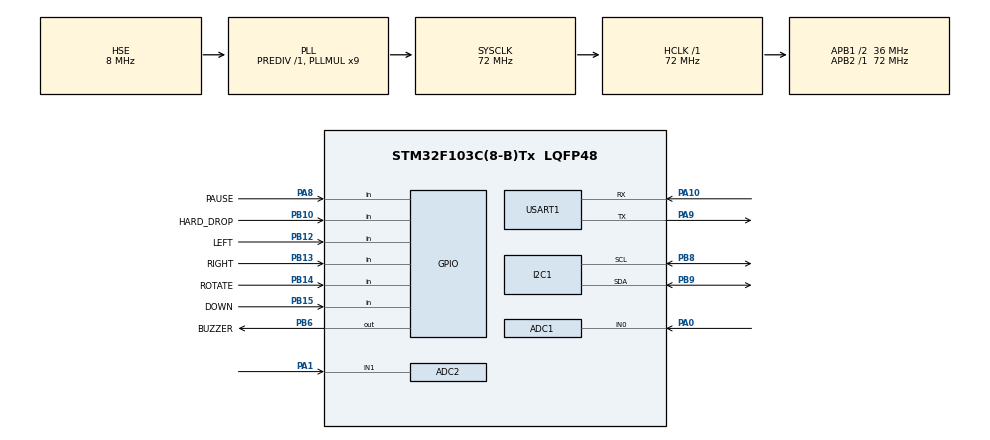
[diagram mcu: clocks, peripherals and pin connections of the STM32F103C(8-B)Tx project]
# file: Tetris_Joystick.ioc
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ADC1.Channel-0\#ChannelRegularConversion=ADC_CHANNEL_0
ADC1.NbrOfConversionFlag=1
ADC1.Rank-0\#ChannelRegularConversion=1
ADC1.SamplingTime-0\#ChannelRegularConversion=ADC_SAMPLETIME_55CYCLES_5
ADC1.master=1
ADC2.Channel-0\#ChannelRegularConversion=ADC_CHANNEL_1
ADC2.NbrOfConversionFlag=1
ADC2.Rank-0\#ChannelRegularConversion=1
ADC2.SamplingTime-0\#ChannelRegularConversion=ADC_SAMPLETIME_55CYCLES_5
FREERTOS.Queues01=xInputQueue,16,uint16_t,0,Dynamic,NULL,NULL;xFrameQueue,1,uint16_t,0,Dynamic,NULL,NULL
FREERTOS.Tasks01=InputTask,27,192,StartInputTask,Default,NULL,Dynamic,NULL,NULL;GameTask,26,320,StartGameTask,Default,NULL,Dynamic,NULL,NULL;DisplayTask,25,384,StartDisplayTask,Default,NULL,Dynamic,NULL,NULL
FREERTOS.configCHECK_FOR_STACK_OVERFLOW=2
FREERTOS.configIDLE_SHOULD_YIELD=0
FREERTOS.configTOTAL_HEAP_SIZE=8192
FREERTOS.configUSE_MALLOC_FAILED_HOOK=1
Mcu.Family=STM32F1
Mcu.Name=STM32F103C(8-B)Tx
Mcu.Package=LQFP48
NVIC.PriorityGroup=NVIC_PRIORITYGROUP_4
NVIC.TIM2_IRQn=true\:15\:0\:false\:false\:true\:false\:false\:true\:true
NVIC.TimeBase=TIM2_IRQn
NVIC.TimeBaseIP=TIM2
NVIC.USART1_IRQn=true\:6\:0\:false\:false\:true\:true\:true\:true
PA0-WKUP.Signal=ADCx_IN0
PA1.Signal=ADCx_IN1
PA10.Mode=Asynchronous
PA10.Signal=USART1_RX
PA13.Mode=Serial_Wire
PA13.Signal=SYS_JTMS-SWDIO
PA14.Mode=Serial_Wire
PA14.Signal=SYS_JTCK-SWCLK
PA8.GPIO_Label=PAUSE
PA8.GPIO_PuPd=GPIO_PULLUP
PA8.Signal=GPIO_Input
PA9.Mode=Asynchronous
PA9.Signal=USART1_TX
PB10.GPIO_Label=HARD_DROP
PB10.GPIO_PuPd=GPIO_PULLUP
PB10.Signal=GPIO_Input
PB12.GPIO_Label=LEFT
PB12.GPIO_PuPd=GPIO_PULLUP
PB12.Signal=GPIO_Input
PB13.GPIO_Label=RIGHT
PB13.GPIO_PuPd=GPIO_PULLUP
PB13.Signal=GPIO_Input
PB14.GPIO_Label=ROTATE
PB14.GPIO_PuPd=GPIO_PULLUP
PB14.Signal=GPIO_Input
PB15.GPIO_Label=DOWN
PB15.GPIO_PuPd=GPIO_PULLUP
PB15.Signal=GPIO_Input
PB6.Signal=GPIO_Output
PB6.GPIO_Label=BUZZER
PB6.PinState=GPIO_PIN_SET
PB8.Mode=I2C
PB8.Signal=I2C1_SCL
PB9.Mode=I2C
PB9.Signal=I2C1_SDA
PD0-OSC_IN.Mode=HSE-External-Oscillator
PD0-OSC_IN.Signal=RCC_OSC_IN
PD1-OSC_OUT.Mode=HSE-External-Oscillator
PD1-OSC_OUT.Signal=RCC_OSC_OUT
ProjectManager.HeapSize=0x200
ProjectManager.StackSize=0x400
ProjectManager.TargetToolchain=MDK-ARM V5.32
RCC.ADCPresc=RCC_ADCPCLK2_DIV6
RCC.AHBFreq_Value=72000000
RCC.APB1CLKDivider=RCC_HCLK_DIV2
RCC.APB1Freq_Value=36000000
RCC.APB1TimFreq_Value=72000000
RCC.APB2Freq_Value=72000000
RCC.APB2TimFreq_Value=72000000
RCC.HCLKFreq_Value=72000000
RCC.PLLMUL=RCC_PLL_MUL9
RCC.PLLSourceVirtual=RCC_PLLSOURCE_HSE
RCC.SYSCLKFreq_VALUE=72000000
RCC.SYSCLKSource=RCC_SYSCLKSOURCE_PLLCLK
RCC.USBFreq_Value=72000000
SH.ADCx_IN0.0=ADC1_IN0,IN0
SH.ADCx_IN1.0=ADC2_IN1,IN1
USART1.VirtualMode=VM_ASYNC
VP_FREERTOS_VS_CMSIS_V2.Mode=CMSIS_V2
VP_SYS_VS_tim2.Mode=TIM2
board=custom

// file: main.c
/* USER CODE BEGIN Header */
/**
  ******************************************************************************
  * @file           : main.c
  * @brief          : Main program body
  ******************************************************************************
  * @attention
  *
  * Copyright (c) 2026 STMicroelectronics.
  * All rights reserved.
  *
  * This software is licensed under terms that can be found in the LICENSE file
  * in the root directory of this software component.
  * If no LICENSE file comes with this software, it is provided AS-IS.
  *
  ******************************************************************************
  */
/* USER CODE END Header */
#include "main.h"
#include "cmsis_os.h"

/* USER CODE BEGIN Includes */
#include "app_shared.h"
#include "app_diagnostics.h"
#include "hal_buzzer.h"

/* USER CODE END Includes */

ADC_HandleTypeDef hadc1;
ADC_HandleTypeDef hadc2;

I2C_HandleTypeDef hi2c1;

UART_HandleTypeDef huart1;

/* Definitions for InputTask */
osThreadId_t InputTaskHandle;
const osThreadAttr_t InputTask_attributes = {
  .name = "InputTask",
  .stack_size = APP_INPUT_STACK_BYTES,
  .priority = (osPriority_t) APP_INPUT_PRIORITY,
};
/* Definitions for GameTask */
osThreadId_t GameTaskHandle;
const osThreadAttr_t GameTask_attributes = {
  .name = "GameTask",
  .stack_size = APP_GAME_STACK_BYTES,
  .priority = (osPriority_t) APP_GAME_PRIORITY,
};
/* Definitions for DisplayTask */
osThreadId_t DisplayTaskHandle;
const osThreadAttr_t DisplayTask_attributes = {
  .name = "DisplayTask",
  .stack_size = APP_DISPLAY_STACK_BYTES,
  .priority = (osPriority_t) APP_DISPLAY_PRIORITY,
};
/* Definitions for xInputQueue */
osMessageQueueId_t xInputQueueHandle;
const osMessageQueueAttr_t xInputQueue_attributes = {
  .name = "xInputQueue"
};
/* Definitions for xFrameQueue */
osMessageQueueId_t xFrameQueueHandle;
const osMessageQueueAttr_t xFrameQueue_attributes = {
  .name = "xFrameQueue"
};

void SystemClock_Config(void);
static void MX_GPIO_Init(void);
static void MX_ADC1_Init(void);
static void MX_ADC2_Init(void);
static void MX_I2C1_Init(void);
static void MX_USART1_UART_Init(void);
void StartInputTask(void *argument);
void StartGameTask(void *argument);
void StartDisplayTask(void *argument);

int main(void)
{

  /* MCU Configuration--------------------------------------------------------*/

  /* Reset of all peripherals, Initializes the Flash interface and the Systick. */
  HAL_Init();
  MX_GPIO_Init(); /* Drive active-low buzzer HIGH before clock/peripheral setup. */

  /* Configure the system clock */
  SystemClock_Config();

  /* Initialize all configured peripherals */
  MX_I2C1_Init();
  MX_USART1_UART_Init();
  MX_ADC1_Init();
  MX_ADC2_Init();
  /* USER CODE BEGIN 2 */
  if (HAL_ADCEx_Calibration_Start(&hadc1)!=HAL_OK ||
      HAL_ADCEx_Calibration_Start(&hadc2)!=HAL_OK) Error_Handler();

  /* USER CODE END 2 */

  /* Ca nhom phai nam: init phan cung -> kernel -> 2 Queue -> 3 Task
   * -> scheduler. Task chua chay cho den khi kernel duoc start. */
  /* Init scheduler */
  if (osKernelInitialize()!=osOK) Error_Handler();

  /* Queue input: 16 phan tu uint16_t. Queue frame: 1 token uint16_t.
   * Snapshot lon duoc copy qua API rieng, khong nham size token voi frame. */
  /* Create the queue(s) */
  /* creation of xInputQueue */
  xInputQueueHandle = osMessageQueueNew (16, sizeof(uint16_t), &xInputQueue_attributes);

  /* creation of xFrameQueue */
  xFrameQueueHandle = osMessageQueueNew (1, sizeof(uint16_t), &xFrameQueue_attributes);

  /* Tao dung mot lan. Cac ham task_*_run trong app/ khong tu tao thread. */
  /* Create the thread(s) */
  /* creation of InputTask */
  InputTaskHandle = osThreadNew(StartInputTask, NULL, &InputTask_attributes);

  /* creation of GameTask */
  GameTaskHandle = osThreadNew(StartGameTask, NULL, &GameTask_attributes);

  /* creation of DisplayTask */
  DisplayTaskHandle = osThreadNew(StartDisplayTask, NULL, &DisplayTask_attributes);

  /* USER CODE BEGIN RTOS_THREADS */
  if (!xInputQueueHandle || !xFrameQueueHandle || !InputTaskHandle ||
      !GameTaskHandle || !DisplayTaskHandle) app_fault(APP_FAULT_RTOS);
  /* add threads, ... */
  /* USER CODE END RTOS_THREADS */

  /* Start scheduler */
  if (osKernelStart()!=osOK) app_fault(APP_FAULT_RTOS);

  /* We should never get here as control is now taken by the scheduler */

  /* Infinite loop */
  while (1)
  {

  }
}

void SystemClock_Config(void)
{
  RCC_OscInitTypeDef RCC_OscInitStruct = {0};
  RCC_ClkInitTypeDef RCC_ClkInitStruct = {0};
  RCC_PeriphCLKInitTypeDef PeriphClkInit = {0};

  /** Initializes the RCC Oscillators according to the specified parameters
  * in the RCC_OscInitTypeDef structure.
  */
  RCC_OscInitStruct.OscillatorType = RCC_OSCILLATORTYPE_HSE;
  RCC_OscInitStruct.HSEState = RCC_HSE_ON;
  RCC_OscInitStruct.HSEPredivValue = RCC_HSE_PREDIV_DIV1;
  RCC_OscInitStruct.HSIState = RCC_HSI_ON;
  RCC_OscInitStruct.PLL.PLLState = RCC_PLL_ON;
  RCC_OscInitStruct.PLL.PLLSource = RCC_PLLSOURCE_HSE;
  RCC_OscInitStruct.PLL.PLLMUL = RCC_PLL_MUL9;
  if (HAL_RCC_OscConfig(&RCC_OscInitStruct) != HAL_OK)
  {
    Error_Handler();
  }

  /** Initializes the CPU, AHB and APB buses clocks
  */
  RCC_ClkInitStruct.ClockType = RCC_CLOCKTYPE_HCLK|RCC_CLOCKTYPE_SYSCLK
                              |RCC_CLOCKTYPE_PCLK1|RCC_CLOCKTYPE_PCLK2;
  RCC_ClkInitStruct.SYSCLKSource = RCC_SYSCLKSOURCE_PLLCLK;
  RCC_ClkInitStruct.AHBCLKDivider = RCC_SYSCLK_DIV1;
  RCC_ClkInitStruct.APB1CLKDivider = RCC_HCLK_DIV2;
  RCC_ClkInitStruct.APB2CLKDivider = RCC_HCLK_DIV1;

  if (HAL_RCC_ClockConfig(&RCC_ClkInitStruct, FLASH_LATENCY_2) != HAL_OK)
  {
    Error_Handler();
  }
  PeriphClkInit.PeriphClockSelection = RCC_PERIPHCLK_ADC;
  PeriphClkInit.AdcClockSelection = RCC_ADCPCLK2_DIV6;
  if (HAL_RCCEx_PeriphCLKConfig(&PeriphClkInit)!=HAL_OK) Error_Handler();
}

static void MX_ADC1_Init(void)
{

  ADC_ChannelConfTypeDef sConfig = {0};

  /** Common config
  */
  hadc1.Instance = ADC1;
  hadc1.Init.ScanConvMode = ADC_SCAN_DISABLE;
  hadc1.Init.ContinuousConvMode = DISABLE;
  hadc1.Init.DiscontinuousConvMode = DISABLE;
  hadc1.Init.ExternalTrigConv = ADC_SOFTWARE_START;
  hadc1.Init.DataAlign = ADC_DATAALIGN_RIGHT;
  hadc1.Init.NbrOfConversion = 1;
  if (HAL_ADC_Init(&hadc1) != HAL_OK)
  {
    Error_Handler();
  }

  /** Configure Regular Channel
  */
  sConfig.Channel = ADC_CHANNEL_0;
  sConfig.Rank = ADC_REGULAR_RANK_1;
  sConfig.SamplingTime = ADC_SAMPLETIME_55CYCLES_5;
  if (HAL_ADC_ConfigChannel(&hadc1, &sConfig) != HAL_OK)
  {
    Error_Handler();
  }

}

static void MX_ADC2_Init(void)
{

  ADC_ChannelConfTypeDef sConfig = {0};

  /** Common config
  */
  hadc2.Instance = ADC2;
  hadc2.Init.ScanConvMode = ADC_SCAN_DISABLE;
  hadc2.Init.ContinuousConvMode = DISABLE;
  hadc2.Init.DiscontinuousConvMode = DISABLE;
  hadc2.Init.ExternalTrigConv = ADC_SOFTWARE_START;
  hadc2.Init.DataAlign = ADC_DATAALIGN_RIGHT;
  hadc2.Init.NbrOfConversion = 1;
  if (HAL_ADC_Init(&hadc2) != HAL_OK)
  {
    Error_Handler();
  }

  /** Configure Regular Channel
  */
  sConfig.Channel = ADC_CHANNEL_1;
  sConfig.Rank = ADC_REGULAR_RANK_1;
  sConfig.SamplingTime = ADC_SAMPLETIME_55CYCLES_5;
  if (HAL_ADC_ConfigChannel(&hadc2, &sConfig) != HAL_OK)
  {
    Error_Handler();
  }

}

static void MX_I2C1_Init(void)
{

  hi2c1.Instance = I2C1;
  hi2c1.Init.ClockSpeed = 100000;
  hi2c1.Init.DutyCycle = I2C_DUTYCYCLE_2;
  hi2c1.Init.OwnAddress1 = 0;
  hi2c1.Init.AddressingMode = I2C_ADDRESSINGMODE_7BIT;
  hi2c1.Init.DualAddressMode = I2C_DUALADDRESS_DISABLE;
  hi2c1.Init.OwnAddress2 = 0;
  hi2c1.Init.GeneralCallMode = I2C_GENERALCALL_DISABLE;
  hi2c1.Init.NoStretchMode = I2C_NOSTRETCH_DISABLE;
  if (HAL_I2C_Init(&hi2c1) != HAL_OK)
  {
    Error_Handler();
  }

}

static void MX_USART1_UART_Init(void)
{

  huart1.Instance = USART1;
  huart1.Init.BaudRate = 115200;
  huart1.Init.WordLength = UART_WORDLENGTH_8B;
  huart1.Init.StopBits = UART_STOPBITS_1;
  huart1.Init.Parity = UART_PARITY_NONE;
  huart1.Init.Mode = UART_MODE_TX_RX;
  huart1.Init.HwFlowCtl = UART_HWCONTROL_NONE;
  huart1.Init.OverSampling = UART_OVERSAMPLING_16;
  if (HAL_UART_Init(&huart1) != HAL_OK)
  {
    Error_Handler();
  }

}

static void MX_GPIO_Init(void)
{
  GPIO_InitTypeDef GPIO_InitStruct = {0};

  /* GPIO Ports Clock Enable */
  __HAL_RCC_GPIOD_CLK_ENABLE();
  __HAL_RCC_GPIOB_CLK_ENABLE();
  __HAL_RCC_GPIOA_CLK_ENABLE();

  /* PB6 HIGH = tat module buzzer LOW-trigger; preload truoc khi enable output. */
  HAL_GPIO_WritePin(BUZZER_GPIO_Port, BUZZER_Pin, GPIO_PIN_SET);
  GPIO_InitStruct.Pin = BUZZER_Pin;
  GPIO_InitStruct.Mode = GPIO_MODE_OUTPUT_PP;
  GPIO_InitStruct.Pull = GPIO_NOPULL;
  GPIO_InitStruct.Speed = GPIO_SPEED_FREQ_LOW;
  HAL_GPIO_Init(BUZZER_GPIO_Port, &GPIO_InitStruct);

  /*Configure GPIO pins : HARD_DROP_Pin LEFT_Pin RIGHT_Pin ROTATE_Pin
                           DOWN_Pin */
  GPIO_InitStruct.Pin = HARD_DROP_Pin|LEFT_Pin|RIGHT_Pin|ROTATE_Pin
                          |DOWN_Pin;
  GPIO_InitStruct.Mode = GPIO_MODE_INPUT;
  GPIO_InitStruct.Pull = GPIO_PULLUP;
  HAL_GPIO_Init(GPIOB, &GPIO_InitStruct);

  /*Configure GPIO pin : PAUSE_Pin */
  GPIO_InitStruct.Pin = PAUSE_Pin;
  GPIO_InitStruct.Mode = GPIO_MODE_INPUT;
  GPIO_InitStruct.Pull = GPIO_PULLUP;
  HAL_GPIO_Init(PAUSE_GPIO_Port, &GPIO_InitStruct);

}

void StartInputTask(void *argument)
{
  /* USER CODE BEGIN 5 */
  /* Call the module in this existing CubeMX Task; never create a duplicate. */
  task_input_run(argument);
  /* USER CODE END 5 */
}

void StartGameTask(void *argument)
{
  /* USER CODE BEGIN StartGameTask */
  /* Call the module in this existing CubeMX Task; never create a duplicate. */
  task_game_run(argument);
  /* USER CODE END StartGameTask */
}

void StartDisplayTask(void *argument)
{
  /* USER CODE BEGIN StartDisplayTask */
  /* Call the module in this existing CubeMX Task; never create a duplicate. */
  task_display_run(argument);
  /* USER CODE END StartDisplayTask */
}

void HAL_TIM_PeriodElapsedCallback(TIM_HandleTypeDef *htim)
{
  if (htim->Instance == TIM2)
  {
    HAL_IncTick();
  }
}

void Error_Handler(void)
{
  /* USER CODE BEGIN Error_Handler_Debug */
  tone(0U,0U);
  /* User can add his own implementation to report the HAL error return state */
  __disable_irq();
  while (1)
  {
  }
  /* USER CODE END Error_Handler_Debug */
}
